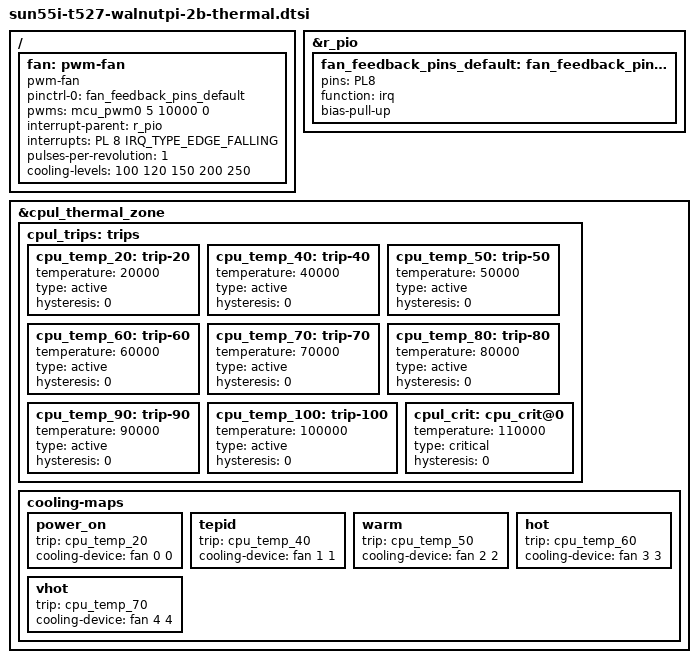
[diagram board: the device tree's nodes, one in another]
&r_pio {
	fan_feedback_pins_default: fan_feedback_pins_default@0 {
		pins = "PL8";
		function = "irq";
		bias-pull-up;
		
	};
};
/{
	fan: pwm-fan {
		compatible = "pwm-fan";
		pinctrl-names = "default";
		pinctrl-0 = <&fan_feedback_pins_default>;
		pwms = <&mcu_pwm0 5 10000 0>;
		#cooling-cells = <2>;
		interrupt-parent = <&r_pio>;
		interrupts = <PL 8 IRQ_TYPE_EDGE_FALLING>;
		pulses-per-revolution = <1>;
		cooling-levels = <100 120 150 200 250>;
	};
};


&cpul_thermal_zone {
	cpul_trips: trips {
		cpu_temp_20: trip-20 {
			temperature = <20000>;
			type = "active";
			hysteresis = <0>;
		};
		cpu_temp_40: trip-40 {
			temperature = <40000>;
			type = "active";
			hysteresis = <0>;
		};
		cpu_temp_50: trip-50 {
			temperature = <50000>;
			type = "active";
			hysteresis = <0>;
		};
		cpu_temp_60: trip-60 {
			temperature = <60000>;
			type = "active";
			hysteresis = <0>;
		};
		cpu_temp_70: trip-70 {
			temperature = <70000>;
			type = "active";
			hysteresis = <0>;
		};
		cpu_temp_80: trip-80 {
			temperature = <80000>;
			type = "active";
			hysteresis = <0>;
		};
		cpu_temp_90: trip-90 {
			temperature = <90000>;
			type = "active";
			hysteresis = <0>;
		};
		cpu_temp_100: trip-100 {
			temperature = <100000>;
			type = "active";
			hysteresis = <0>;
		};
		
		cpul_crit: cpu_crit@0 {
			temperature = <110000>;
			type = "critical";
			hysteresis = <0>;
		};
	};
	cooling-maps {

		power_on {
			trip = <&cpu_temp_20>;
			cooling-device = <&fan 0 0>;
		};
		tepid {
			trip = <&cpu_temp_40>;
			cooling-device = <&fan 1 1>;
		};
		warm {
			trip = <&cpu_temp_50>;
			cooling-device = <&fan 2 2>;
		};
		hot {
			trip = <&cpu_temp_60>;
			cooling-device = <&fan 3 3>;
		};
		vhot {
			trip = <&cpu_temp_70>;
			cooling-device = <&fan 4 4>;
		};
	};
};

